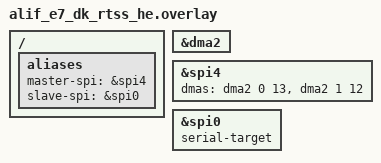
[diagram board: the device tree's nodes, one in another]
/* Copyright (C) 2024 Alif Semiconductor - All Rights Reserved.
 * Use, distribution and modification of this code is permitted under the
 * terms stated in the Alif Semiconductor Software License Agreement
 *
 * You should have received a copy of the Alif Semiconductor Software
 * License Agreement with this file. If not, please write to:
 * contact@alifsemi.com, or visit: https://alifsemi.com/license
 *
 */

/* setting SPI4 as master and SPI0 instance as slave.
 *
 */

/ {
	aliases {
		master-spi = &spi4;
		slave-spi = &spi0;
	};
};

&dma2 {
	status = "okay";
};

&spi4 {
	status = "okay";

	dmas = <&dma2 0 13>, <&dma2 1 12>;
	//dmas = <&dma0 0 25>, <&dma0 1 24>;
	dma-names = "txdma", "rxdma";
};

&spi0 {
	status = "okay";
        serial-target;
        //dmas = <&dma0 2 20>, <&dma0 3 16>;
	//dma-names = "txdma", "rxdma";
};

